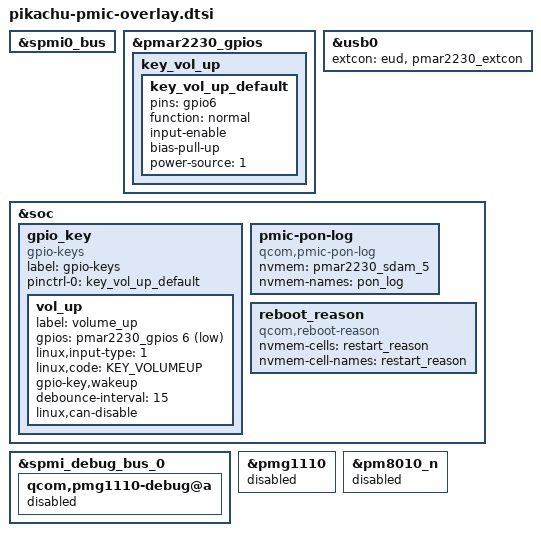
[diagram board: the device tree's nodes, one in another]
// SPDX-License-Identifier: BSD-3-Clause
/*
 * Copyright (c) Qualcomm Technologies, Inc. and/or its subsidiaries.
 */

#include <dt-bindings/gpio/gpio.h>
#include <dt-bindings/input/input.h>

&spmi0_bus {
	#include "pm8010.dtsi"
	#include "pmar2230.dtsi"
	#include "pmg1110.dtsi"
};

&pmar2230_gpios {
	key_vol_up {
		key_vol_up_default: key_vol_up_default {
			pins = "gpio6";
			function = "normal";
			input-enable;
			bias-pull-up;
			power-source = <1>;
		};
	};
};

&usb0 {
	extcon = <&eud>, <&pmar2230_extcon>;
};

&soc {
	gpio_key {
		compatible = "gpio-keys";
		label = "gpio-keys";
		pinctrl-names = "default";
		pinctrl-0 = <&key_vol_up_default>;

		vol_up {
			label = "volume_up";
			gpios = <&pmar2230_gpios 6 GPIO_ACTIVE_LOW>;
			linux,input-type = <1>;
			linux,code = <KEY_VOLUMEUP>;
			gpio-key,wakeup;
			debounce-interval = <15>;
			linux,can-disable;
		};
	};

	pmic-pon-log {
		compatible = "qcom,pmic-pon-log";
		nvmem = <&pmar2230_sdam_5>;
		nvmem-names = "pon_log";
	};

	reboot_reason {
		compatible = "qcom,reboot-reason";
		nvmem-cells = <&restart_reason>;
		nvmem-cell-names = "restart_reason";
	};
};

&spmi_debug_bus_0 {
	qcom,pmg1110-debug@a {
		status = "disabled";
	};
};

&pmg1110 {
	status = "disabled";
};

&pm8010_n {
	status = "disabled";
};
